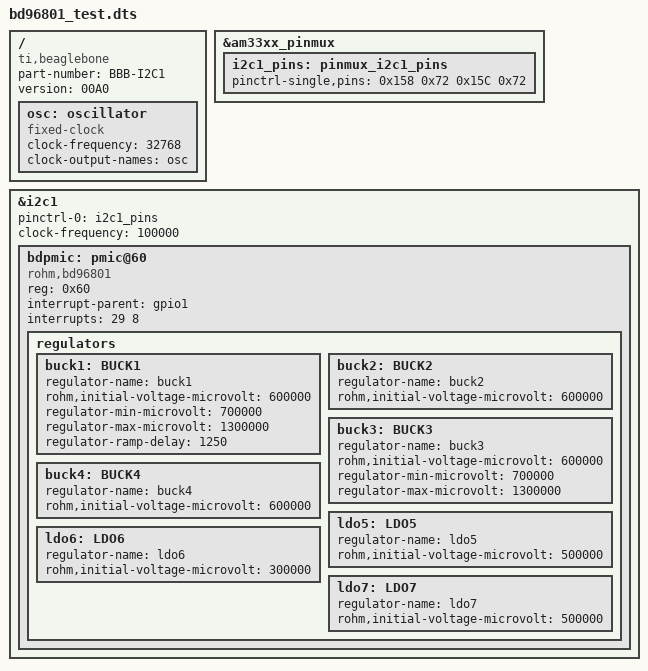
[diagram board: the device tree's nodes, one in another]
/dts-v1/;
/plugin/;

/{ /* this is our device tree overlay root node */

	compatible = "ti,beaglebone", "ti,beaglebone-black";
	part-number = "BBB-I2C1"; // you can choose any name here but it should be memorable
 	version = "00A0";

	fragment@0 {
		target = <&am33xx_pinmux>; // this is a link to an already defined node in the device tree, so that node is overlayed with our modification

		__overlay__ {
			i2c1_pins: pinmux_i2c1_pins {
				pinctrl-single,pins = <
          			0x158 0x72 /* spi0_d1.i2c1_sda */ 
          			0x15C 0x72 /* spi0_cs0.i2c1_sdl */
        			>;
			};
		};
	};
	fragment@1 {
		target-path = "/";
		__overlay__ {
			/* external oscillator */
			osc: oscillator {
				compatible = "fixed-clock";
				#clock-cells = <1>;
				clock-frequency  = <32768>;
				clock-output-names = "osc";
			};
		};
	};

	fragment@2 {
		target = <&i2c1>;

		__overlay__ {
			pinctrl-0 = <&i2c1_pins>;
			clock-frequency = <100000>;
			status = "okay";



			bdpmic: pmic@60 { /* the "test" defined as child of the i2c1 bus */
				compatible = "rohm,bd96801";
				reg = <0x60>;
				/* GPIO 1_29 - (connector 8, pin 26) for irq */
				interrupt-parent = <&gpio1>;
/*				interrupts = <29 GPIO_ACTIVE_LOW>; */
				interrupts = <29 8>;
				/* 1500 ms cold reset */

				regulators {
					buck1: BUCK1 {
						regulator-name = "buck1";
						rohm,initial-voltage-microvolt = <600000>;
						regulator-min-microvolt = <700000>;
						regulator-max-microvolt = <1300000>;
/*						regulator-boot-on; */
/*						regulator-always-on; */
						regulator-ramp-delay = <1250>;
					};
					buck2: BUCK2 {
						regulator-name = "buck2";
						rohm,initial-voltage-microvolt = <600000>;
					};
					buck3: BUCK3 {
						regulator-name = "buck3";
						rohm,initial-voltage-microvolt = <600000>;
						regulator-min-microvolt = <700000>;
						regulator-max-microvolt = <1300000>;
					};
					buck4: BUCK4 {
						regulator-name = "buck4";
						rohm,initial-voltage-microvolt = <600000>;
					};
					ldo5: LDO5 {
						regulator-name = "ldo5";
						rohm,initial-voltage-microvolt = <500000>;
/*						regulator-always-on; */
					};

					ldo6: LDO6 {
						regulator-name = "ldo6";
						rohm,initial-voltage-microvolt = <300000>;
/*						regulator-always-on; */
					};

					ldo7: LDO7 {
						regulator-name = "ldo7";
						rohm,initial-voltage-microvolt = <500000>;
					};
				};
			};
		};
	};
}; /* root node end */
